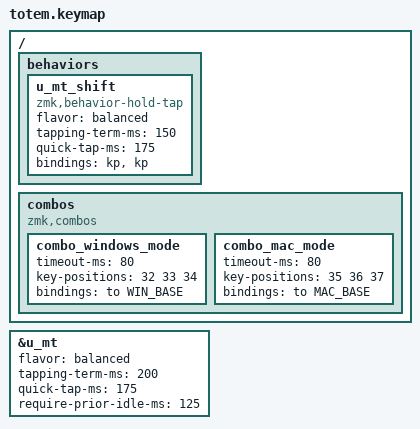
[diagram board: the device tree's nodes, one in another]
// TOTEM keymap: Miryoku-style layers with a Windows mode and a Mac mode.
//
// The layers are written out below in the TOTEM's physical shape. Miryoku
// (miryoku/, an unmodified copy of https://github.com/manna-harbour/miryoku_zmk)
// provides the building blocks and turns these tables into the keymap;
// mac_mode.dtsi adds a Mac copy of every layer.
//
// Once a change has been saved in ZMK Studio, the keyboard keeps using its
// saved copy instead of this file until "Restore Stock Settings" is clicked
// in Studio (see README).

#define MIRYOKU_CLIPBOARD_WIN

// Layers, in the order ZMK and Studio list them
#define MIRYOKU_LAYER_LIST \
MIRYOKU_X(BASE,  "Base") \
MIRYOKU_X(TAP,   "Tap") \
MIRYOKU_X(MEDIA, "Media") \
MIRYOKU_X(NAV,   "Nav") \
MIRYOKU_X(MOUSE, "Mouse") \
MIRYOKU_X(NUM,   "Num") \
MIRYOKU_X(SYM,   "Sym") \
MIRYOKU_X(FUN,   "Fun")

#define U_BASE  0
#define U_TAP   1
#define U_MEDIA 2
#define U_NAV   3
#define U_MOUSE 4
#define U_NUM   5
#define U_SYM   6
#define U_FUN   7

// Key order of the layer tables (the TOTEM's physical shape; 20 and 31 are the
// outer pinky keys):
//
//         0   1   2   3   4       5   6   7   8   9
//        10  11  12  13  14      15  16  17  18  19
//    20  21  22  23  24  25      26  27  28  29  30  31
//                32  33  34      35  36  37
#define TOTEM_MAPPING( \
         K00, K01, K02, K03, K04,      K05, K06, K07, K08, K09, \
         K10, K11, K12, K13, K14,      K15, K16, K17, K18, K19, \
    K20, K21, K22, K23, K24, K25,      K26, K27, K28, K29, K30, K31, \
                   K32, K33, K34,      K35, K36, K37 \
) \
         K00  K01  K02  K03  K04       K05  K06  K07  K08  K09 \
         K10  K11  K12  K13  K14       K15  K16  K17  K18  K19 \
    K20  K21  K22  K23  K24  K25       K26  K27  K28  K29  K30  K31 \
                   K32  K33  K34       K35  K36  K37
#define MIRYOKU_MAPPING TOTEM_MAPPING

// Names used in the tables:
//   U_MT(mod, key)    key when tapped, mod when held (home row mods)
//   U_MT_SHIFT(key)   the same for Shift, without the pause after typing (see below)
//   U_LT(layer, key)  key when tapped, layer while held
//   &u_to_U_<layer>   switch to that layer with a double tap (as locks: the
//                     key right above each thumb key locks that thumb's layer)
//   U_UND/CUT/CPY/PST/RDO  undo, cut, copy, paste, redo
//   U_BOOT            ZMK Studio unlock (see below)
//   U_NA, U_NU        no key (U_NA: on the hand that holds the layer key)

#define U_MT_SHIFT(TAP) &u_mt_shift LSHFT TAP

#define MIRYOKU_LAYER_BASE \
         &kp Q,         &kp W,         &kp E,          &kp R,         &kp T,           &kp Y,        &kp U,         &kp I,          &kp O,           &kp SQT, \
         U_MT(LGUI, A), U_MT(LALT, S), U_MT(LCTRL, D), U_MT_SHIFT(F), &kp G,           &kp H,        U_MT_SHIFT(J), U_MT(LCTRL, K), U_MT(LALT, L),   U_MT(LGUI, P), \
&kp ESC, &kp Z,         U_MT(RALT, X), &kp C,          &kp V,         &kp B,           &kp N,        &kp M,         &kp COMMA,      U_MT(RALT, DOT), &kp SEMI,      &kp BSPC, \
                                       U_LT(U_MEDIA, GRAVE), U_LT(U_MOUSE, TAB), U_LT(U_NAV, SPACE),     U_LT(U_SYM, RET), U_LT(U_NUM, SLASH), U_LT(U_FUN, BSLH)

#define MIRYOKU_LAYER_TAP \
         &kp Q,         &kp W,         &kp E,          &kp R,         &kp T,           &kp Y,        &kp U,         &kp I,          &kp O,           &kp SQT, \
         &kp A,         &kp S,         &kp D,          &kp F,         &kp G,           &kp H,        &kp J,         &kp K,          &kp L,           &kp P, \
&kp ESC, &kp Z,         &kp X,         &kp C,          &kp V,         &kp B,           &kp N,        &kp M,         &kp COMMA,      &kp DOT,         &kp SEMI,      &kp BSPC, \
                                       &kp GRAVE,            &kp TAB,            &kp SPACE,              &kp RET,          &kp SLASH,          &kp BSLH

#define MIRYOKU_LAYER_MEDIA \
         U_BOOT,        &u_to_U_TAP,   U_NA,           &u_to_U_BASE,  U_NA,            U_RDO,        U_PST,         U_CPY,          U_CUT,           U_UND, \
         &kp LGUI,      &kp LALT,      &kp LCTRL,      &kp LSHFT,     &kp PSCRN,       &u_out_tog,   &kp C_PP,      &kp C_STOP,     &kp C_PREV,      &kp C_NEXT, \
&kp ESC, U_NA,          &kp RALT,      &u_to_U_MEDIA,  &u_to_U_MOUSE, &u_to_U_NAV,     &u_bt_sel_0,  &u_bt_sel_1,   &u_bt_sel_2,    &u_bt_sel_3,     &bt BT_CLR,    &kp BSPC, \
                                       U_NA,                 &kp TAB,            &kp SPACE,              &kp C_MUTE,       &kp C_VOL_DN,       &kp C_VOL_UP

#define MIRYOKU_LAYER_NAV \
         U_BOOT,        &u_to_U_TAP,   U_NA,           &u_to_U_BASE,  U_NA,            U_RDO,        U_PST,         U_CPY,          U_CUT,           U_UND, \
         &kp LGUI,      &kp LALT,      &kp LCTRL,      &kp LSHFT,     &kp PSCRN,       &kp DEL,      &kp LEFT,      &kp DOWN,       &kp UP,          &kp RIGHT, \
&kp ESC, U_NA,          &kp RALT,      &u_to_U_MEDIA,  &u_to_U_MOUSE, &u_to_U_NAV,     &kp INS,      &kp HOME,      &kp PG_DN,      &kp PG_UP,       &kp END,       &kp BSPC, \
                                       &kp K_APP,            &kp TAB,            U_NA,                   &kp RET,          &kp SLASH,          &kp BSLH

#define MIRYOKU_LAYER_MOUSE \
         U_BOOT,        &u_to_U_TAP,   U_NA,           &u_to_U_BASE,  U_NA,            U_RDO,        U_PST,         U_CPY,          U_CUT,           U_UND, \
         &kp LGUI,      &kp LALT,      &kp LCTRL,      &kp LSHFT,     &kp PSCRN,       &kp C_BRI_UP, U_MS_L,        U_MS_D,         U_MS_U,          U_MS_R, \
&kp ESC, U_NA,          &kp RALT,      &u_to_U_MEDIA,  &u_to_U_MOUSE, &u_to_U_NAV,     &kp C_BRI_DN, U_WH_L,        U_WH_D,         U_WH_U,          U_WH_R,        &kp BSPC, \
                                       &kp K_APP,            U_NA,               &kp SPACE,              U_BTN2,           U_BTN1,             U_BTN3

#define MIRYOKU_LAYER_NUM \
         &kp LBKT,      &kp N7,        &kp N8,         &kp N9,        &kp N0,          U_NA,         &u_to_U_BASE,  U_NA,           &u_to_U_TAP,     U_BOOT, \
         &kp RBKT,      &kp N4,        &kp N5,         &kp N6,        &kp MINUS,       &kp PSCRN,    &kp LSHFT,     &kp LCTRL,      &kp LALT,        &kp LGUI, \
&kp ESC, &kp DOT,       &kp N1,        &kp N2,         &kp N3,        &kp EQUAL,       &u_to_U_SYM,  &u_to_U_NUM,   &u_to_U_FUN,    &kp RALT,        U_NA,          &kp BSPC, \
                                       U_NU,                 &kp TAB,            &kp SPACE,              U_NA,             U_NA,               U_NA

#define MIRYOKU_LAYER_SYM \
         &kp LBRC,      &kp AMPS,      &kp ASTRK,      &kp LPAR,      &kp RPAR,        U_NA,         &u_to_U_BASE,  U_NA,           &u_to_U_TAP,     U_BOOT, \
         &kp RBRC,      &kp DLLR,      &kp PRCNT,      &kp CARET,     &kp UNDER,       &kp PSCRN,    &kp LSHFT,     &kp LCTRL,      &kp LALT,        &kp LGUI, \
&kp ESC, &kp CAPS,      &kp EXCL,      &kp AT,         &kp HASH,      &kp PLUS,        &u_to_U_SYM,  &u_to_U_NUM,   &u_to_U_FUN,    &kp RALT,        U_NA,          &kp BSPC, \
                                       U_NU,                 &kp TAB,            &kp SPACE,              U_NA,             U_NA,               U_NA

#define MIRYOKU_LAYER_FUN \
         U_NU,          &kp F7,        &kp F8,         &kp F9,        &kp F10,         U_NA,         &u_to_U_BASE,  U_NA,           &u_to_U_TAP,     U_BOOT, \
         U_NU,          &kp F4,        &kp F5,         &kp F6,        &kp F11,         &kp PSCRN,    &kp LSHFT,     &kp LCTRL,      &kp LALT,        &kp LGUI, \
&kp ESC, U_NU,          &kp F1,        &kp F2,         &kp F3,        &kp F12,         &u_to_U_SYM,  &u_to_U_NUM,   &u_to_U_FUN,    &kp RALT,        U_NA,          &kp BSPC, \
                                       U_NU,                 &kp TAB,            &kp SPACE,              U_NA,             U_NA,               U_NA

// Load Miryoku's macros early so the Boot key can be replaced before the
// layers are generated. Reflashing is done with the reset button instead, and
// the free slot unlocks ZMK Studio.
#include "miryoku/miryoku.h"
#undef U_BOOT
#define U_BOOT &studio_unlock

// Windows layers 0-7
#include "miryoku/miryoku.dtsi"

// Mac layers 8-15 (the same layers with Ctrl/Cmd swapped and Mac shortcuts)
#include "mac_mode.dtsi"

// Home row mods. A home row key becomes its modifier as soon as another key
// is pressed and released while it is held ("balanced"), or after
// tapping-term-ms when held on its own. (Miryoku's default, "tap-preferred",
// always waits the full tapping-term-ms.)
//   quick-tap-ms:          tap a key, then hold it again within this time to
//                          repeat the letter; double letters stay letters
//   require-prior-idle-ms: a key pressed within this time after the previous
//                          key is always a letter, which keeps fast typing
//                          from triggering modifiers by accident
// Applies to Windows and Mac mode. The thumb layer keys (&u_lt) keep
// Miryoku's timing.
&u_mt {
    flavor = "balanced";
    tapping-term-ms = <200>;
    quick-tap-ms = <175>;
    require-prior-idle-ms = <125>;
};

/ {
    behaviors {
        // Shift on F and J: like the other home row mods, but without
        // require-prior-idle-ms, so a capital letter works right after a space
        // or another letter, however fast it comes, and with a shorter
        // tapping-term-ms.
        u_mt_shift: u_mt_shift {
            compatible = "zmk,behavior-hold-tap";
            #binding-cells = <2>;
            flavor = "balanced";
            tapping-term-ms = <150>;
            quick-tap-ms = <175>;
            bindings = <&kp>, <&kp>;
        };
    };

    combos {
        compatible = "zmk,combos";

        // All 3 left thumb keys at once: Windows mode
        combo_windows_mode {
            timeout-ms = <80>;
            key-positions = <32 33 34>;
            bindings = <&to WIN_BASE>;
        };

        // All 3 right thumb keys at once: Mac mode
        combo_mac_mode {
            timeout-ms = <80>;
            key-positions = <35 36 37>;
            bindings = <&to MAC_BASE>;
        };
    };
};
